# STM32H755_CM7 register map
File version: 1.4
CPU: CM7 r0p1, little endian, MPU, FPU, 4 interrupt priority bits
Registers are 32-bit, read-write, reset 0x0 unless marked. A register's access mark holds for its fields unless they carry their own. Offsets are from the block's base; [hi:lo] are bit positions; {n}, {i} and the like mark numbered series; 'fields as' and 'values as' point back to an identical list.

## TIM6 — Basic timers
Base 0x40001000
Same registers: TIM7 0x40001400
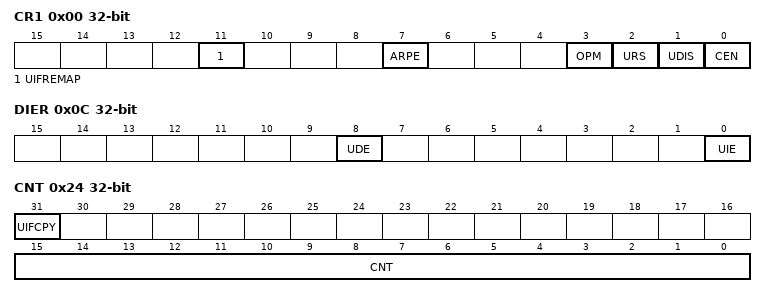
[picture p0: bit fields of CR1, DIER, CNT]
0x00 CR1 — control register 1
  [11] UIFREMAP — UIF status bit remapping
  [7] ARPE — Auto-reload preload enable
  [3] OPM — One-pulse mode
  [2] URS — Update request source
  [1] UDIS — Update disable
  [0] CEN — Counter enable
0x04 CR2 — control register 2
  [6:4] MMS — Master mode selection
0x0C DIER — DMA/Interrupt enable register
  [8] UDE — Update DMA request enable
  [0] UIE — Update interrupt enable
0x10 SR — status register
  [0] UIF — Update interrupt flag
0x14 EGR wo — event generation register
  [0] UG — Update generation
0x24 CNT — counter
  [31] UIFCPY — UIF Copy
  [15:0] CNT — Low counter value
0x28 PSC — prescaler
  [15:0] PSC — Prescaler value
0x2C ARR — auto-reload register
  [15:0] ARR — Low Auto-reload value

## NVIC — Nested Vectored Interrupt Controller
Base 0xE000E100
{0x0+4i} ISER{i} (i=0..2) — Interrupt Set-Enable Register
  [31:0] SETENA
0x0C ISER3 — Interrupt Set-Enable Register
{0x80+4i} ICER{i} (i=0..2) — Interrupt Clear-Enable Register
  [31:0] CLRENA
0x8C ICER3 — Interrupt Clear-Enable Register
{0x100+4i} ISPR{i} (i=0..2) — Interrupt Set-Pending Register
  [31:0] SETPEND
0x10C ISPR3 — Interrupt Set-Pending Register
{0x180+4i} ICPR{i} (i=0..2) — Interrupt Clear-Pending Register
  [31:0] CLRPEND
0x1C0 ICPR3 — Interrupt Clear-Pending Register
{0x200+4i} IABR{i} ro (i=0..2) — Interrupt Active Bit Register
  [31:0] ACTIVE
0x20C IABR3 — Interrupt Active Bit Register
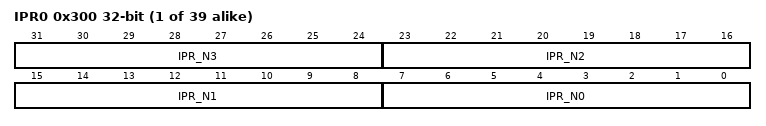
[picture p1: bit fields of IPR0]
{0x300+4i} IPR{i} (i=0..38) — Interrupt Priority Register
  [8n+7:8n] IPR_N{n} (n=0..3)

## DBGMCU — Microcontroller Debug Unit
Base 0x5C001000
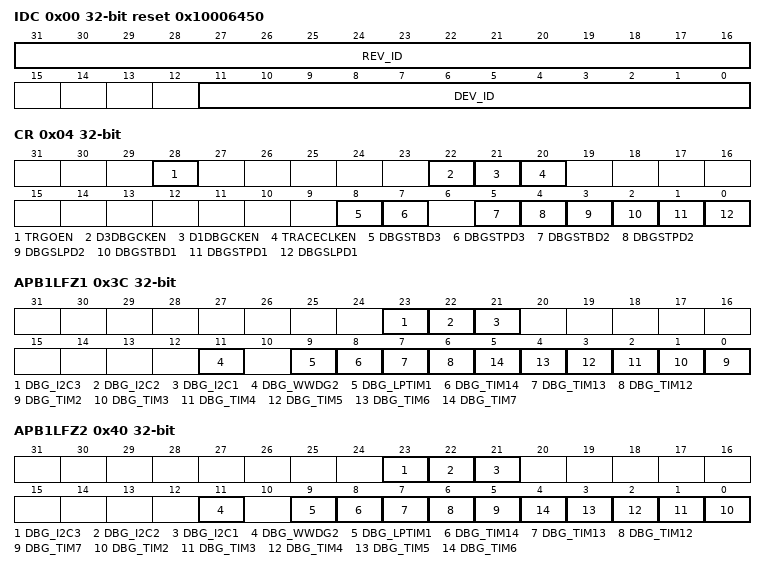
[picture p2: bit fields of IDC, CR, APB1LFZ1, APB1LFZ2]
0x00 IDC ro reset 0x10006450 — DBGMCU Identity Code Register
  [31:16] REV_ID — Revision
  [11:0] DEV_ID — Device ID
0x04 CR — DBGMCU Configuration Register
  [28] TRGOEN — External trigger output enable
  [22] D3DBGCKEN — D3 debug clock enable
  [21] D1DBGCKEN — D1 debug clock enable
  [20] TRACECLKEN — Trace port clock enable
  [8] DBGSTBD3 — Allow debug in D3 Standby mode
  [7] DBGSTPD3 — Allow debug in D3 Stop mode
  [5] DBGSTBD2 — Allow D2 domain debug in Standby mode
  [4] DBGSTPD2 — Allow D2 domain debug in Stop mode
  [3] DBGSLPD2 — Allow D2 domain debug in Sleep mode
  [2] DBGSTBD1 — Allow D1 domain debug in Standby mode
  [1] DBGSTPD1 — Allow D1 domain debug in Stop mode
  [0] DBGSLPD1 — Allow D1 domain debug in Sleep mode
0x34 APB3FZ1 — DBGMCU APB3 peripheral freeze register CPU1
  [6] WWDG1 — WWDG1 stop in debug
0x38 APB3FZ2 — DBGMCU APB3 peripheral freeze register CPU2
  [6] WWDG1 — WWDG1 stop in debug
0x3C APB1LFZ1 — DBGMCU APB1L peripheral freeze register
  [23] DBG_I2C3 — I2C3 SMBUS timeout stop in debug
  [22] DBG_I2C2 — I2C2 SMBUS timeout stop in debug
  [21] DBG_I2C1 — I2C1 SMBUS timeout stop in debug
  [11] DBG_WWDG2 — WWDG2 stop in debug
  [9] DBG_LPTIM1 — LPTIM1 stop in debug
  [8] DBG_TIM14 — TIM14 stop in debug
  [7] DBG_TIM13 — TIM13 stop in debug
  [6] DBG_TIM12 — TIM12 stop in debug
  [n-2] DBG_TIM{n} (n=2..7) — TIM{n} stop in debug
0x40 APB1LFZ2 — DBGMCU APB1L peripheral freeze register CPU2
  [23] DBG_I2C3 — I2C3 SMBUS timeout stop in debug
  [22] DBG_I2C2 — I2C2 SMBUS timeout stop in debug
  [21] DBG_I2C1 — I2C1 SMBUS timeout stop in debug
  [11] DBG_WWDG2 — WWDG2 stop in debug
  [9] DBG_LPTIM1 — LPTIM1 stop in debug
  [8] DBG_TIM14 — TIM14 stop in debug
  [7] DBG_TIM13 — TIM13 stop in debug
  [6] DBG_TIM12 — TIM12 stop in debug
  [5] DBG_TIM7 — TIM4 stop in debug
  [n-2] DBG_TIM{n} (n=2..6) — TIM{n} stop in debug
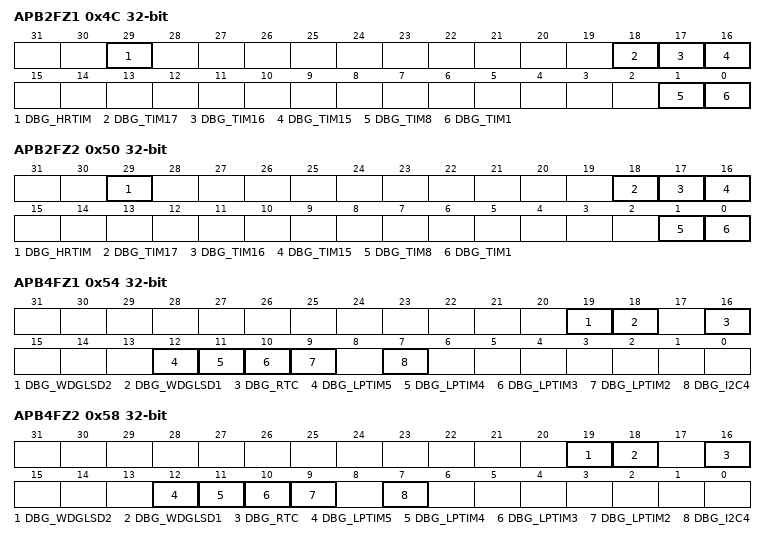
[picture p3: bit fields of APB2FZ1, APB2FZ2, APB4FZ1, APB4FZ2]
0x4C APB2FZ1 — DBGMCU APB2 peripheral freeze register
  [29] DBG_HRTIM — HRTIM stop in debug
  [18] DBG_TIM17 — TIM17 stop in debug
  [17] DBG_TIM16 — TIM16 stop in debug
  [16] DBG_TIM15 — TIM15 stop in debug
  [1] DBG_TIM8 — TIM8 stop in debug
  [0] DBG_TIM1 — TIM1 stop in debug
0x50 APB2FZ2 — DBGMCU APB2 peripheral freeze register CPU2
  fields as APB2FZ1
0x54 APB4FZ1 — DBGMCU APB4 peripheral freeze register
  [19] DBG_WDGLSD2 — Independent watchdog for D2 stop in debug
  [18] DBG_WDGLSD1 — Independent watchdog for D1 stop in debug
  [16] DBG_RTC — RTC stop in debug
  [12] DBG_LPTIM5 — LPTIM5 stop in debug
  [11] DBG_LPTIM4 — LPTIM4 stop in debug
  [10] DBG_LPTIM3 — LPTIM2 stop in debug
  [9] DBG_LPTIM2 — LPTIM2 stop in debug
  [7] DBG_I2C4 — I2C4 SMBUS timeout stop in debug
0x58 APB4FZ2 — DBGMCU APB4 peripheral freeze register CPU2
  [19] DBG_WDGLSD2 — LS watchdog for D2 stop in debug
  [18] DBG_WDGLSD1 — LS watchdog for D1 stop in debug
  [16] DBG_RTC — RTC stop in debug
  [12] DBG_LPTIM5 — LPTIM5 stop in debug
  [11] DBG_LPTIM4 — LPTIM4 stop in debug
  [10] DBG_LPTIM3 — LPTIM2 stop in debug
  [9] DBG_LPTIM2 — LPTIM2 stop in debug
  [7] DBG_I2C4 — I2C4 SMBUS timeout stop in debug
